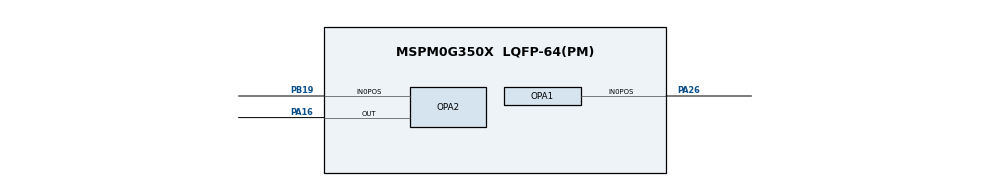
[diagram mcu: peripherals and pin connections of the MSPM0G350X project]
/**
 * @cliArgs --device "MSPM0G350X" --part "Default" --package "LQFP-64(PM)" --product "mspm0_sdk@2.08.00.02"
 * @versions {"tool":"1.25.0+4268"}
 */

/**
 * Import the modules used in this configuration.
 */
const Board         = scripting.addModule("/ti/driverlib/Board");
const OPA           = scripting.addModule("/ti/driverlib/OPA", {}, false);
const OPA1          = OPA.addInstance();
const OPA2          = OPA.addInstance();
const SYSCTL        = scripting.addModule("/ti/driverlib/SYSCTL");
const ProjectConfig = scripting.addModule("/ti/project_config/ProjectConfig");

/**
 * Write custom configuration values to the imported modules.
 */

OPA1.$name                        = "OPA_0";
OPA1.cfg0PSELChannel              = "IN0_POS";
OPA1.cfg0NSELChannel              = "RBOT";
OPA1.In0PosPinConfig.$name        = "ti_driverlib_gpio_GPIOPinGeneric0";
OPA1.peripheral.$assign           = "OPA0";
OPA1.peripheral.In0PosPin.$assign = "PA26";

OPA2.$name                        = "OPA_1";
OPA2.cfg0PSELChannel              = "IN0_POS";
OPA2.cfg0NSELChannel              = "RTAP";
OPA2.cfg0MSELChannel              = "RTOP";
OPA2.cfg0OutputPin                = "ENABLED";
OPA2.cfg0Gain                     = "N1_P2";
OPA2.In0PosPinConfig.$name        = "ti_driverlib_gpio_GPIOPinGeneric2";
OPA2.peripheral.$assign           = "OPA1";
OPA2.peripheral.In0PosPin.$assign = "PB19";
OPA2.peripheral.OutPin.$assign    = "PA16";
OPA2.OutPinConfig.$name           = "ti_driverlib_gpio_GPIOPinGeneric3";

SYSCTL.clockTreeEn = true;

/**
 * Pinmux solution for unlocked pins/peripherals. This ensures that minor changes to the automatic solver in a future
 * version of the tool will not impact the pinmux you originally saw.  These lines can be completely deleted in order to
 * re-solve from scratch.
 */
Board.peripheral.$suggestSolution          = "DEBUGSS";
Board.peripheral.swclkPin.$suggestSolution = "PA20";
Board.peripheral.swdioPin.$suggestSolution = "PA19";
